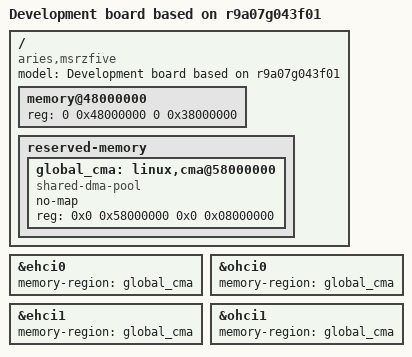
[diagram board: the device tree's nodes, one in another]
// SPDX-License-Identifier: GPL-2.0
/*
 * Device Tree Source for the RZ/Five Evaluation board
 *
 * Copyright (C) 2021 Renesas Electronics Corp.
 */

/dts-v1/;
#include "../renesas/r9a07g043f01.dtsi"
#include "msrzfive.dtsi"

/ {
	model = "Development board based on r9a07g043f01";
	compatible = "aries,msrzfive",
		     "renesas,r9a07g043f01",
		     "renesas,r9a07g043f";

	memory@48000000 {
		device_type = "memory";
		/* first 128MB is reserved for secure area. */
		reg = <0 0x48000000 0 0x38000000>;
	};

	reserved-memory {
		#address-cells = <2>;
		#size-cells = <2>;
		ranges;

		global_cma: linux,cma@58000000 {
			compatible = "shared-dma-pool";
			no-map;
			reg = <0x0 0x58000000 0x0 0x08000000>;
		};
	};
};


&ehci0 {
	memory-region = <&global_cma>;
};

&ohci0 {
	memory-region = <&global_cma>;
};

&ehci1 {
	memory-region = <&global_cma>;
};

&ohci1 {
	memory-region = <&global_cma>;
};
